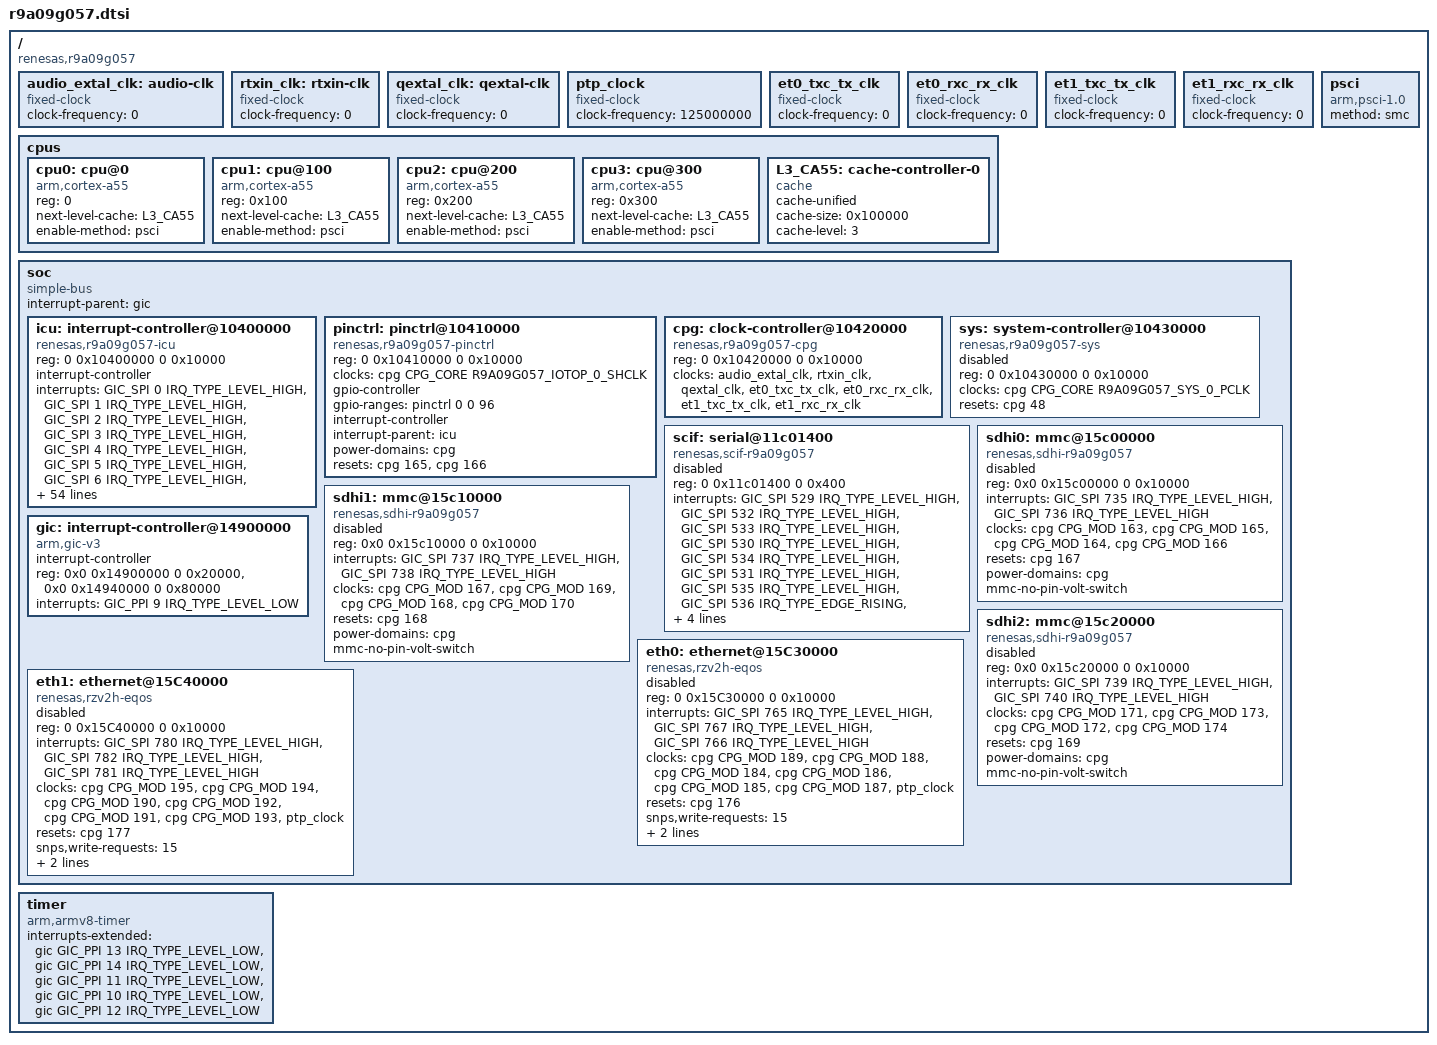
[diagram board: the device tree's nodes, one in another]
// SPDX-License-Identifier: (GPL-2.0-only OR BSD-2-Clause)
/*
 * Device Tree Source for the RZ/V2H SoC
 *
 * Copyright (C) 2024 Renesas Electronics Corp.
 */

#include <dt-bindings/clock/renesas,r9a09g057-cpg.h>
#include <dt-bindings/interrupt-controller/arm-gic.h>

/ {
	compatible = "renesas,r9a09g057";
	#address-cells = <2>;
	#size-cells = <2>;

	audio_extal_clk: audio-clk {
		compatible = "fixed-clock";
		#clock-cells = <0>;
		/* This value must be overridden by the board */
		clock-frequency = <0>;
	};

	rtxin_clk: rtxin-clk {
		compatible = "fixed-clock";
		#clock-cells = <0>;
		/* This value must be overridden by the board */
		clock-frequency = <0>;
	};

	qextal_clk: qextal-clk {
		compatible = "fixed-clock";
		#clock-cells = <0>;
		/* This value must be overridden by the board */
		clock-frequency = <0>;
	};

	/* ptp_clock input */
	ptp_clock: ptp_clock {
		compatible = "fixed-clock";
		#clock-cells = <0>;
		/* This value must be overridden by the board */
		clock-frequency = <125000000>;
	};

	/* et0_txc_tx_clk clock input */
	et0_txc_tx_clk: et0_txc_tx_clk {
		compatible = "fixed-clock";
		#clock-cells = <0>;
		/* This value must be overridden by the board */
		clock-frequency = <0>;
	};

	/* et0_rxc_rx_clk clock input */
	et0_rxc_rx_clk: et0_rxc_rx_clk {
		compatible = "fixed-clock";
		#clock-cells = <0>;
		/* This value must be overridden by the board */
		clock-frequency = <0>;
	};

	/* et1_txc_tx_clk clock input */
	et1_txc_tx_clk: et1_txc_tx_clk {
		compatible = "fixed-clock";
		#clock-cells = <0>;
		/* This value must be overridden by the board */
		clock-frequency = <0>;
	};

	/* et1_rxc_rx_clk clock input */
	et1_rxc_rx_clk: et1_rxc_rx_clk {
		compatible = "fixed-clock";
		#clock-cells = <0>;
		/* This value must be overridden by the board */
		clock-frequency = <0>;
	};

	cpus {
		#address-cells = <1>;
		#size-cells = <0>;

		cpu0: cpu@0 {
			compatible = "arm,cortex-a55";
			reg = <0>;
			device_type = "cpu";
			next-level-cache = <&L3_CA55>;
			enable-method = "psci";
		};

		cpu1: cpu@100 {
			compatible = "arm,cortex-a55";
			reg = <0x100>;
			device_type = "cpu";
			next-level-cache = <&L3_CA55>;
			enable-method = "psci";
		};

		cpu2: cpu@200 {
			compatible = "arm,cortex-a55";
			reg = <0x200>;
			device_type = "cpu";
			next-level-cache = <&L3_CA55>;
			enable-method = "psci";
		};

		cpu3: cpu@300 {
			compatible = "arm,cortex-a55";
			reg = <0x300>;
			device_type = "cpu";
			next-level-cache = <&L3_CA55>;
			enable-method = "psci";
		};

		L3_CA55: cache-controller-0 {
			compatible = "cache";
			cache-unified;
			cache-size = <0x100000>;
			cache-level = <3>;
		};
	};

	psci {
		compatible = "arm,psci-1.0", "arm,psci-0.2";
		method = "smc";
	};

	soc: soc {
		compatible = "simple-bus";
		interrupt-parent = <&gic>;
		#address-cells = <2>;
		#size-cells = <2>;
		ranges;

		icu: interrupt-controller@10400000 {
			compatible = "renesas,r9a09g057-icu";
			reg = <0 0x10400000 0 0x10000>;
			#interrupt-cells = <2>;
			#address-cells = <0>;
			interrupt-controller;
			interrupts = <GIC_SPI 0 IRQ_TYPE_LEVEL_HIGH>,
				     <GIC_SPI 1 IRQ_TYPE_LEVEL_HIGH>,
				     <GIC_SPI 2 IRQ_TYPE_LEVEL_HIGH>,
				     <GIC_SPI 3 IRQ_TYPE_LEVEL_HIGH>,
				     <GIC_SPI 4 IRQ_TYPE_LEVEL_HIGH>,
				     <GIC_SPI 5 IRQ_TYPE_LEVEL_HIGH>,
				     <GIC_SPI 6 IRQ_TYPE_LEVEL_HIGH>,
				     <GIC_SPI 7 IRQ_TYPE_LEVEL_HIGH>,
				     <GIC_SPI 8 IRQ_TYPE_LEVEL_HIGH>,
				     <GIC_SPI 9 IRQ_TYPE_LEVEL_HIGH>,
				     <GIC_SPI 10 IRQ_TYPE_LEVEL_HIGH>,
				     <GIC_SPI 11 IRQ_TYPE_LEVEL_HIGH>,
				     <GIC_SPI 12 IRQ_TYPE_LEVEL_HIGH>,
				     <GIC_SPI 13 IRQ_TYPE_LEVEL_HIGH>,
				     <GIC_SPI 14 IRQ_TYPE_LEVEL_HIGH>,
				     <GIC_SPI 15 IRQ_TYPE_LEVEL_HIGH>,
				     <GIC_SPI 16 IRQ_TYPE_LEVEL_HIGH>,
				     <GIC_SPI 419 IRQ_TYPE_LEVEL_HIGH>,
				     <GIC_SPI 420 IRQ_TYPE_LEVEL_HIGH>,
				     <GIC_SPI 421 IRQ_TYPE_LEVEL_HIGH>,
				     <GIC_SPI 422 IRQ_TYPE_LEVEL_HIGH>,
				     <GIC_SPI 423 IRQ_TYPE_LEVEL_HIGH>,
				     <GIC_SPI 424 IRQ_TYPE_LEVEL_HIGH>,
				     <GIC_SPI 425 IRQ_TYPE_LEVEL_HIGH>,
				     <GIC_SPI 426 IRQ_TYPE_LEVEL_HIGH>,
				     <GIC_SPI 427 IRQ_TYPE_LEVEL_HIGH>,
				     <GIC_SPI 428 IRQ_TYPE_LEVEL_HIGH>,
				     <GIC_SPI 429 IRQ_TYPE_LEVEL_HIGH>,
				     <GIC_SPI 430 IRQ_TYPE_LEVEL_HIGH>,
				     <GIC_SPI 431 IRQ_TYPE_LEVEL_HIGH>,
				     <GIC_SPI 432 IRQ_TYPE_LEVEL_HIGH>,
				     <GIC_SPI 433 IRQ_TYPE_LEVEL_HIGH>,
				     <GIC_SPI 434 IRQ_TYPE_LEVEL_HIGH>,
				     <GIC_SPI 435 IRQ_TYPE_LEVEL_HIGH>,
				     <GIC_SPI 436 IRQ_TYPE_LEVEL_HIGH>,
				     <GIC_SPI 437 IRQ_TYPE_LEVEL_HIGH>,
				     <GIC_SPI 438 IRQ_TYPE_LEVEL_HIGH>,
				     <GIC_SPI 439 IRQ_TYPE_LEVEL_HIGH>,
				     <GIC_SPI 440 IRQ_TYPE_LEVEL_HIGH>,
				     <GIC_SPI 441 IRQ_TYPE_LEVEL_HIGH>,
				     <GIC_SPI 442 IRQ_TYPE_LEVEL_HIGH>,
				     <GIC_SPI 443 IRQ_TYPE_LEVEL_HIGH>,
				     <GIC_SPI 444 IRQ_TYPE_LEVEL_HIGH>,
				     <GIC_SPI 445 IRQ_TYPE_LEVEL_HIGH>,
				     <GIC_SPI 446 IRQ_TYPE_LEVEL_HIGH>,
				     <GIC_SPI 447 IRQ_TYPE_LEVEL_HIGH>,
				     <GIC_SPI 448 IRQ_TYPE_LEVEL_HIGH>,
				     <GIC_SPI 449 IRQ_TYPE_LEVEL_HIGH>,
				     <GIC_SPI 450 IRQ_TYPE_LEVEL_HIGH>,
				     <GIC_SPI 262 IRQ_TYPE_EDGE_RISING>,
				     <GIC_SPI 263 IRQ_TYPE_EDGE_RISING>,
				     <GIC_SPI 264 IRQ_TYPE_EDGE_RISING>,
				     <GIC_SPI 265 IRQ_TYPE_EDGE_RISING>,
				     <GIC_SPI 266 IRQ_TYPE_LEVEL_HIGH>,
				     <GIC_SPI 451 IRQ_TYPE_LEVEL_HIGH>,
				     <GIC_SPI 452 IRQ_TYPE_LEVEL_HIGH>,
				     <GIC_SPI 453 IRQ_TYPE_LEVEL_HIGH>,
				     <GIC_SPI 454 IRQ_TYPE_LEVEL_HIGH>;
			interrupt-names = "nmi",
					  "port_irq0", "port_irq1", "port_irq2",
					  "port_irq3", "port_irq4", "port_irq5",
					  "port_irq6", "port_irq7", "port_irq8",
					  "port_irq9", "port_irq10", "port_irq11",
					  "port_irq12", "port_irq13", "port_irq14",
					  "port_irq15",
					  "tint0", "tint1", "tint2", "tint3",
					  "tint4", "tint5", "tint6", "tint7",
					  "tint8", "tint9", "tint10", "tint11",
					  "tint12", "tint13", "tint14", "tint15",
					  "tint16", "tint17", "tint18", "tint19",
					  "tint20", "tint21", "tint22", "tint23",
					  "tint24", "tint25", "tint26", "tint27",
					  "tint28", "tint29", "tint30", "tint31",
					  "int-ca55-0", "int-ca55-1",
					  "int-ca55-2", "int-ca55-3",
					  "icu-error-ca55",
					  "gpt-u0-gtciada", "gpt-u0-gtciadb",
					  "gpt-u1-gtciada", "gpt-u1-gtciadb";
			clocks = <&cpg CPG_MOD 0x5>;
			power-domains = <&cpg>;
			resets = <&cpg 0x36>;
		};

		pinctrl: pinctrl@10410000 {
			compatible = "renesas,r9a09g057-pinctrl";
			reg = <0 0x10410000 0 0x10000>;
			clocks = <&cpg CPG_CORE R9A09G057_IOTOP_0_SHCLK>;
			gpio-controller;
			#gpio-cells = <2>;
			gpio-ranges = <&pinctrl 0 0 96>;
			#interrupt-cells = <2>;
			interrupt-controller;
			interrupt-parent = <&icu>;
			power-domains = <&cpg>;
			resets = <&cpg 165>, <&cpg 166>;
		};

		cpg: clock-controller@10420000 {
			compatible = "renesas,r9a09g057-cpg";
			reg = <0 0x10420000 0 0x10000>;
			clocks = <&audio_extal_clk>, <&rtxin_clk>, <&qextal_clk>,
				 <&et0_txc_tx_clk>, <&et0_rxc_rx_clk>,
				 <&et1_txc_tx_clk>, <&et1_rxc_rx_clk>;
			clock-names = "audio_extal", "rtxin", "qextal",
				      "et0_txc_tx_clk", "et0_rxc_rx_clk",
				      "et1_txc_tx_clk", "et1_rxc_rx_clk";
			#clock-cells = <2>;
			#reset-cells = <1>;
			#power-domain-cells = <0>;
		};

		sys: system-controller@10430000 {
			compatible = "renesas,r9a09g057-sys";
			reg = <0 0x10430000 0 0x10000>;
			clocks = <&cpg CPG_CORE R9A09G057_SYS_0_PCLK>;
			resets = <&cpg 48>;
			status = "disabled";
		};

		scif: serial@11c01400 {
			compatible = "renesas,scif-r9a09g057",
				     "renesas,scif-r9a07g044";
			reg = <0 0x11c01400 0 0x400>;
			interrupts = <GIC_SPI 529 IRQ_TYPE_LEVEL_HIGH>,
				     <GIC_SPI 532 IRQ_TYPE_LEVEL_HIGH>,
				     <GIC_SPI 533 IRQ_TYPE_LEVEL_HIGH>,
				     <GIC_SPI 530 IRQ_TYPE_LEVEL_HIGH>,
				     <GIC_SPI 534 IRQ_TYPE_LEVEL_HIGH>,
				     <GIC_SPI 531 IRQ_TYPE_LEVEL_HIGH>,
				     <GIC_SPI 535 IRQ_TYPE_LEVEL_HIGH>,
				     <GIC_SPI 536 IRQ_TYPE_EDGE_RISING>,
				     <GIC_SPI 537 IRQ_TYPE_EDGE_RISING>;
			interrupt-names = "eri", "rxi", "txi", "bri", "dri",
					  "tei", "tei-dri", "rxi-edge", "txi-edge";
			clocks = <&cpg CPG_MOD 143>;
			clock-names = "fck";
			power-domains = <&cpg>;
			resets = <&cpg 149>;
			status = "disabled";
		};

		sdhi0: mmc@15c00000  {
			compatible = "renesas,sdhi-r9a09g057";
			reg = <0x0 0x15c00000 0 0x10000>;
			interrupts = <GIC_SPI 735 IRQ_TYPE_LEVEL_HIGH>,
				     <GIC_SPI 736 IRQ_TYPE_LEVEL_HIGH>;
			clocks = <&cpg CPG_MOD 163>,
				 <&cpg CPG_MOD 165>,
				 <&cpg CPG_MOD 164>,
				 <&cpg CPG_MOD 166>;
			clock-names = "core", "clkh", "cd", "aclk";
			resets = <&cpg 167>;
			power-domains = <&cpg>;
			mmc-no-pin-volt-switch;
			status = "disabled";
		};

		sdhi1: mmc@15c10000 {
			compatible = "renesas,sdhi-r9a09g057";
			reg = <0x0 0x15c10000 0 0x10000>;
			interrupts = <GIC_SPI 737 IRQ_TYPE_LEVEL_HIGH>,
				     <GIC_SPI 738 IRQ_TYPE_LEVEL_HIGH>;
			clocks = <&cpg CPG_MOD 167>,
				 <&cpg CPG_MOD 169>,
				 <&cpg CPG_MOD 168>,
				 <&cpg CPG_MOD 170>;
			clock-names = "core", "clkh", "cd", "aclk";
			resets = <&cpg 168>;
			power-domains = <&cpg>;
			mmc-no-pin-volt-switch;
			status = "disabled";
		};

		sdhi2: mmc@15c20000 {
			compatible = "renesas,sdhi-r9a09g057";
			reg = <0x0 0x15c20000 0 0x10000>;
			interrupts = <GIC_SPI 739 IRQ_TYPE_LEVEL_HIGH>,
				     <GIC_SPI 740 IRQ_TYPE_LEVEL_HIGH>;
			clocks = <&cpg CPG_MOD 171>,
				 <&cpg CPG_MOD 173>,
				 <&cpg CPG_MOD 172>,
				 <&cpg CPG_MOD 174>;
			clock-names = "core", "clkh", "cd", "aclk";
			resets = <&cpg 169>;
			power-domains = <&cpg>;
			mmc-no-pin-volt-switch;
			status = "disabled";
		};

		gic: interrupt-controller@14900000 {
			compatible = "arm,gic-v3";
			#interrupt-cells = <3>;
			#address-cells = <0>;
			interrupt-controller;
			reg = <0x0 0x14900000 0 0x20000>,
			      <0x0 0x14940000 0 0x80000>;
			interrupts = <GIC_PPI 9 IRQ_TYPE_LEVEL_LOW>;
		};

		eth0: ethernet@15C30000 {
			compatible = "renesas,rzv2h-eqos",
					"snps,dwc-qos-ethernet-4.10";
			reg = <0 0x15C30000 0 0x10000>;
			interrupts = <GIC_SPI 765 IRQ_TYPE_LEVEL_HIGH>,
				     <GIC_SPI 767 IRQ_TYPE_LEVEL_HIGH>,
				     <GIC_SPI 766 IRQ_TYPE_LEVEL_HIGH>;
			interrupt-names = "macirq", "eth_wake_irq", "eth_lpi";
			clocks =  <&cpg CPG_MOD 189>,
				  <&cpg CPG_MOD 188>,
				  <&cpg CPG_MOD 184>,
				  <&cpg CPG_MOD 186>,
				  <&cpg CPG_MOD 185>,
				  <&cpg CPG_MOD 187>,
				  <&ptp_clock>;
			clock-names = "master_bus", "slave_bus", "tx",
				      "tx_180", "rx", "rx_180", "ptp_ref";
			resets = <&cpg 176>;
			#address-cells = <1>;
			#size-cells = <0>;
			status = "disabled";
			snps,write-requests = <15>;
			snps,read-requests = <15>;
			snps,burst-map = <0x7>;
		};

		eth1: ethernet@15C40000 {
			compatible = "renesas,rzv2h-eqos",
					"snps,dwc-qos-ethernet-4.10";
			reg = <0 0x15C40000 0 0x10000>;
			interrupts = <GIC_SPI 780 IRQ_TYPE_LEVEL_HIGH>,
				     <GIC_SPI 782 IRQ_TYPE_LEVEL_HIGH>,
				     <GIC_SPI 781 IRQ_TYPE_LEVEL_HIGH>;
			interrupt-names = "macirq", "eth_wake_irq", "eth_lpi";
			clocks =  <&cpg CPG_MOD 195>,
				  <&cpg CPG_MOD 194>,
				  <&cpg CPG_MOD 190>,
				  <&cpg CPG_MOD 192>,
				  <&cpg CPG_MOD 191>,
				  <&cpg CPG_MOD 193>,
				  <&ptp_clock>;
			clock-names = "master_bus", "slave_bus", "tx",
				      "tx_180", "rx", "rx_180", "ptp_ref";
			resets = <&cpg 177>;
			#address-cells = <1>;
			#size-cells = <0>;
			status = "disabled";
			snps,write-requests = <15>;
			snps,read-requests = <15>;
			snps,burst-map = <0x7>;
		};
	};

	timer {
		compatible = "arm,armv8-timer";
		interrupts-extended = <&gic GIC_PPI 13 IRQ_TYPE_LEVEL_LOW>,
				      <&gic GIC_PPI 14 IRQ_TYPE_LEVEL_LOW>,
				      <&gic GIC_PPI 11 IRQ_TYPE_LEVEL_LOW>,
				      <&gic GIC_PPI 10 IRQ_TYPE_LEVEL_LOW>,
				      <&gic GIC_PPI 12 IRQ_TYPE_LEVEL_LOW>;
		interrupt-names = "sec-phys", "phys", "virt", "hyp-phys", "hyp-virt";
	};
};
